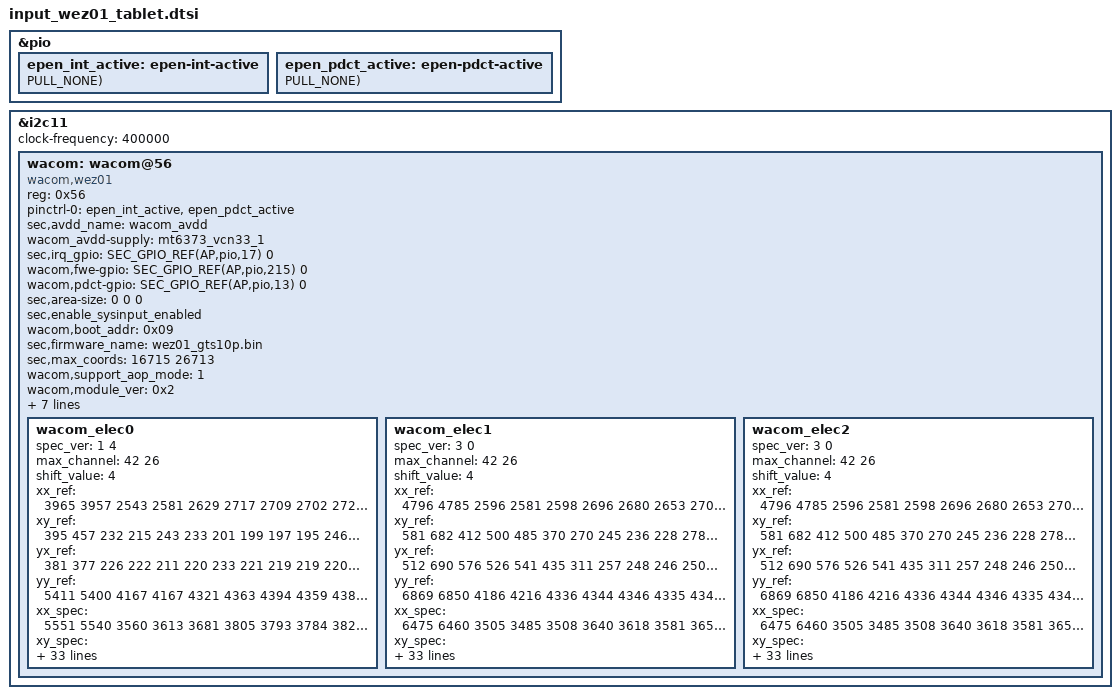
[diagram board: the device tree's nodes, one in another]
&pio {
	epen_int_active: epen-int-active {
		GPIO_CONFIG_PUD(AP,pio,17, FUNC_INPUT_WAKEUP, PULL_NONE);
	};
};

&pio {
	epen_pdct_active: epen-pdct-active {
		GPIO_CONFIG_PUD(AP,pio,13, FUNC_INPUT_WAKEUP, PULL_NONE);
	};
};

&i2c11 {
	status = "ok";
	clock-frequency = <400000>;

	wacom: wacom@56 {
		status = "okay";
		compatible = "wacom,wez01";
		reg = <0x56>;
		pinctrl-names = "default";
		pinctrl-0 = <&epen_int_active &epen_pdct_active>;
		sec,avdd_name = "wacom_avdd";
		wacom_avdd-supply = <&mt6373_vcn33_1>;
		/* gpios */
		sec,irq_gpio = <SEC_GPIO_REF(AP,pio,17) 0>;
		wacom,fwe-gpio = <SEC_GPIO_REF(AP,pio,215) 0>;
		wacom,pdct-gpio = <SEC_GPIO_REF(AP,pio,13) 0>;

		sec,area-size = <0 0 0>; /* recalculate in driver */

		/*support feature*/
		sec,enable_sysinput_enabled;

		/* features */
		wacom,boot_addr = <0x09>;
	};
};

/* /home/dpi/qb5_8814/workspace/P4_1716/android/kernel/kmodule/input/sec_input_2024/wacom/wez01_tablet/dts/input-mtk-wacom.gts10p(wifi).dtsi */
&wacom {
	sec,firmware_name = "wez01_gts10p.bin";
	sec,max_coords = <16715 26713>;

	wacom,support_aop_mode = "1"; /* S-note want to check to use aop */
	wacom,module_ver = <0x2>; /* this value use to distinguish open/short test (0x1 : only open test, 0x2: open/short test) */
	wacom,table_swap = <0x2>; /* bit set: 0 ~ 1(kbd) 1(dex station)*/
	wacom,support_cover_noti;
	wacom,support_cover_detection;
	wacom,support_pogo_cover;
	wacom,support_dual_garage;
	wacom,support_garage_open_test = <0>;
	chip_on_board;

	wacom_elec0 { /* main */
		spec_ver = <1 4>;
		max_channel = <42 26>; /* x y */
		shift_value = <4>;

		xx_ref = /bits/ 64 < 3965 3957 2543 2581 2629 2717 2709 2702 2728 2821 2703 2725 2820 2675 2598 2569 2634 2645 2617 2651 2668 2701 2706 2739 2741 2707 2741 2743 2676 2658 2671 2672 2658 2659 2611 2561 2645 2439 2447 2474 3703 3706 >;
		xy_ref = /bits/ 64 < 395 457 232 215 243 233 201 199 197 195 246 336 277 387 188 131 134 126 141 189 222 210 203 194 180 189 195 141 206 144 222 165 235 136 143 262 145 264 173 328 465 593 >;
		yx_ref = /bits/ 64 < 381 377 226 222 211 220 233 221 219 219 220 225 205 589 327 330 222 242 265 265 233 226 233 243 447 361 >;
		yy_ref = /bits/ 64 < 5411 5400 4167 4167 4321 4363 4394 4359 4386 4404 4408 4406 4401 4406 4404 4351 4406 4425 4391 4405 4426 4391 4249 4144 4700 4703 >;

		xx_spec = /bits/ 64 < 5551 5540 3560 3613 3681 3805 3793 3784 3820 3949 3785 3816 3949 3745 3638 3596 3687 3703 3664 3711 3736 3782 3789 3834 3838 3790 3837 3840 3746 3721 3740 3741 3722 3722 3655 3586 3703 3415 3426 3464 5184 5188 >;
		xy_spec = /bits/ 64 < 553 640 324 302 341 326 282 278 276 273 345 471 388 543 264 184 187 176 197 265 312 294 284 272 253 265 273 197 289 202 311 231 330 190 201 367 203 369 242 459 651 830 >;
		yx_spec = /bits/ 64 < 534 528 317 311 296 308 327 310 307 307 309 316 288 825 458 462 312 340 371 371 326 317 326 340 626 505 >;
		yy_spec = /bits/ 64 < 7575 7560 5835 5834 6049 6108 6152 6102 6141 6165 6171 6168 6162 6168 6165 6091 6168 6195 6147 6167 6196 6147 5948 5802 6581 6584 >;

		rxx_ref = /bits/ 64 < 10000 10000 10000 10000 10000 10000 10000 10000 10000 10000 10000 10000 10000 10000 10000 10000 10000 10000 10000 10000 10000 10000 10000 10000 10000 10000 10000 10000 10000 10000 10000 10000 10000 10000 10000 10000 10000 10000 10000 10000 10000 10000 >;
		rxy_ref = /bits/ 64 < 10000 10000 10000 10000 10000 10000 10000 10000 10000 10000 10000 10000 10000 10000 10000 10000 10000 10000 10000 10000 10000 10000 10000 10000 10000 10000 10000 10000 10000 10000 10000 10000 10000 10000 10000 10000 10000 10000 10000 10000 10000 10000 >;
		ryx_ref = /bits/ 64 < 10000 10000 10000 10000 10000 10000 10000 10000 10000 10000 10000 10000 10000 10000 10000 10000 10000 10000 10000 10000 10000 10000 10000 10000 10000 10000 >;
		ryy_ref = /bits/ 64 < 10000 10000 10000 10000 10000 10000 10000 10000 10000 10000 10000 10000 10000 10000 10000 10000 10000 10000 10000 10000 10000 10000 10000 10000 10000 10000 >;

		drxx_spec = /bits/ 64 < 3500 3500 3500 3500 3500 3500 3500 3500 3500 3500 3500 3500 3500 3500 3500 3500 3500 3500 3500 3500 3500 3500 3500 3500 3500 3500 3500 3500 3500 3500 3500 3500 3500 3500 3500 3500 3500 3500 3500 3500 3500 3500 >;
		drxy_spec = /bits/ 64 < 4000 4000 4000 4000 4000 4000 4000 4000 4000 4000 4000 4000 4000 4000 4000 4000 4000 4000 4000 4000 4000 4000 4000 4000 4000 4000 4000 4000 4000 4000 4000 4000 4000 4000 4000 4000 4000 4000 4000 4000 4000 4000 >;
		dryx_spec = /bits/ 64 < 4000 4000 4000 4000 4000 4000 4000 4000 4000 4000 4000 4000 4000 4000 4000 4000 4000 4000 4000 4000 4000 4000 4000 4000 4000 4000 >;
		dryy_spec = /bits/ 64 < 3500 3500 3500 3500 3500 3500 3500 3500 3500 3500 3500 3500 3500 3500 3500 3500 3500 3500 3500 3500 3500 3500 3500 3500 3500 3500 >;

		drxy_spec_edg = /bits/ 64 < 990000 990000 990000 990000 990000 990000 990000 990000 990000 990000 990000 990000 990000 990000 990000 990000 990000 990000 990000 990000 990000 990000 990000 990000 990000 990000 990000 990000 990000 990000 990000 990000 990000 990000 990000 990000 990000 990000 990000 990000 990000 990000 >;
		dryx_spec_edg = /bits/ 64 < 990000 990000 990000 990000 990000 990000 990000 990000 990000 990000 990000 990000 990000 990000 990000 990000 990000 990000 990000 990000 990000 990000 990000 990000 990000 990000 >;
		xy_ref_edg = /bits/ 64 < 348 384 179 168 111 74 64 68 98 132 153 23 164 38 137 31 66 90 93 152 174 171 163 140 103 68 59 68 97 111 94 80 86 72 44 58 69 77 65 124 362 288 >;
		yx_ref_edg = /bits/ 64 < 310 365 208 188 192 189 191 211 206 206 207 208 175 275 227 221 146 176 211 220 208 211 206 210 362 303 >;

		xx_spec_self = /bits/ 64 < 22000 20000 20000 21000 21000 20000 21000 21000 20000 20000 20000 20000 21000 21000 20000 21000 21000 21000 22000 22000 22000 22000 22000 23000 22000 23000 24000 24000 24000 23000 23000 23000 23000 23000 24000 24000 24000 24000 24000 24000 22000 23000 >;
		yy_spec_self = /bits/ 64 < 25000 25000 25000 25000 25000 25000 25000 25000 25000 25000 25000 25000 25000 25000 25000 25000 25000 25000 25000 25000 25000 25000 25000 25000 25000 25000 >;
	};

	wacom_elec1 { /* assay */
		spec_ver = <3 0>;
		max_channel = <42 26>; /* x y */
		shift_value = <4>;

		xx_ref = /bits/ 64 < 4796 4785 2596 2581 2598 2696 2680 2653 2705 2837 2705 2702 2836 2707 2652 2672 2677 2698 2674 2680 2701 2641 2638 2676 2674 2639 2676 2677 2626 2614 2627 2663 2686 2688 2664 2686 2687 2577 2564 2567 4669 4671 >;
		xy_ref = /bits/ 64 < 581 682 412 500 485 370 270 245 236 228 278 359 350 469 318 264 234 235 241 237 242 238 241 239 239 240 243 246 239 244 238 242 235 219 218 266 246 267 299 428 744 693 >;
		yx_ref = /bits/ 64 < 512 690 576 526 541 435 311 257 248 246 250 287 263 689 358 364 233 237 254 259 302 423 544 581 741 535 >;
		yy_ref = /bits/ 64 < 6869 6850 4186 4216 4336 4344 4346 4335 4348 4357 4356 4352 4350 4368 4389 4370 4386 4397 4371 4383 4395 4362 4310 4242 6176 6181 >;

		xx_spec = /bits/ 64 < 6475 6460 3505 3485 3508 3640 3618 3581 3651 3831 3653 3648 3829 3654 3580 3608 3614 3643 3610 3618 3647 3565 3562 3612 3610 3562 3613 3615 3545 3529 3547 3595 3626 3629 3596 3626 3628 3479 3461 3465 6303 6306 >;
		xy_spec = /bits/ 64 < 784 921 556 676 655 500 365 332 318 308 375 485 473 634 430 357 316 317 325 320 327 322 325 323 323 324 328 332 323 330 322 326 317 296 294 359 332 361 403 578 1004 936 >;
		yx_spec = /bits/ 64 < 692 931 778 710 730 587 420 347 335 333 338 387 356 930 483 492 314 319 343 350 408 571 734 784 1000 722 >;
		yy_spec = /bits/ 64 < 9273 9248 5651 5692 5853 5865 5867 5852 5869 5882 5881 5876 5873 5897 5925 5899 5921 5936 5901 5918 5934 5889 5819 5727 8338 8345 >;

		rxx_ref = /bits/ 64 < 10000 10000 10000 10000 10000 10000 10000 10000 10000 10000 10000 10000 10000 10000 10000 10000 10000 10000 10000 10000 10000 10000 10000 10000 10000 10000 10000 10000 10000 10000 10000 10000 10000 10000 10000 10000 10000 10000 10000 10000 10000 10000 >;
		rxy_ref = /bits/ 64 < 10000 10000 10000 10000 10000 10000 10000 10000 10000 10000 10000 10000 10000 10000 10000 10000 10000 10000 10000 10000 10000 10000 10000 10000 10000 10000 10000 10000 10000 10000 10000 10000 10000 10000 10000 10000 10000 10000 10000 10000 10000 10000 >;
		ryx_ref = /bits/ 64 < 10000 10000 10000 10000 10000 10000 10000 10000 10000 10000 10000 10000 10000 10000 10000 10000 10000 10000 10000 10000 10000 10000 10000 10000 10000 10000 >;
		ryy_ref = /bits/ 64 < 10000 10000 10000 10000 10000 10000 10000 10000 10000 10000 10000 10000 10000 10000 10000 10000 10000 10000 10000 10000 10000 10000 10000 10000 10000 10000 >;

		drxx_spec = /bits/ 64 < 3500 3500 3500 3500 3500 3500 3500 3500 3500 3500 3500 3500 3500 3500 3500 3500 3500 3500 3500 3500 3500 3500 3500 3500 3500 3500 3500 3500 3500 3500 3500 3500 3500 3500 3500 3500 3500 3500 3500 3500 3500 3500 >;
		drxy_spec = /bits/ 64 < 4000 4000 4000 4000 4000 4000 4000 4000 4000 4000 4000 4000 4000 4000 4000 4000 4000 4000 4000 4000 4000 4000 4000 4000 4000 4000 4000 4000 4000 4000 4000 4000 4000 4000 4000 4000 4000 4000 4000 4000 4000 4000 >;
		dryx_spec = /bits/ 64 < 4000 4000 4000 4000 4000 4000 4000 4000 4000 4000 4000 4000 4000 4000 4000 4000 4000 4000 4000 4000 4000 4000 4000 4000 4000 4000 >;
		dryy_spec = /bits/ 64 < 3500 3500 3500 3500 3500 3500 3500 3500 3500 3500 3500 3500 3500 3500 3500 3500 3500 3500 3500 3500 3500 3500 3500 3500 3500 3500 >;

		drxy_spec_edg = /bits/ 64 < 990000 990000 990000 990000 990000 990000 990000 990000 990000 990000 990000 990000 990000 990000 990000 990000 990000 990000 990000 990000 990000 990000 990000 990000 990000 990000 990000 990000 990000 990000 990000 990000 990000 990000 990000 990000 990000 990000 990000 990000 990000 990000 >;
		dryx_spec_edg = /bits/ 64 < 990000 990000 990000 990000 990000 990000 990000 990000 990000 990000 990000 990000 990000 990000 990000 990000 990000 990000 990000 990000 990000 990000 990000 990000 990000 990000 >;
		xy_ref_edg = /bits/ 64 < 446 550 372 269 224 215 212 209 207 206 202 37 186 120 275 127 200 204 205 204 205 203 205 205 207 204 207 208 206 206 204 207 201 176 165 185 214 233 289 400 691 552 >;
		yx_ref_edg = /bits/ 64 < 450 542 432 514 391 289 257 246 238 233 232 231 225 293 247 246 170 201 235 244 268 345 473 566 673 471 >;

		xx_spec_self = /bits/ 64 < 24000 21000 22000 22000 22000 21000 22000 21000 20000 20000 21000 20000 22000 22000 21000 22000 21000 22000 22000 22000 23000 22000 23000 23000 23000 23000 25000 25000 25000 24000 24000 24000 24000 24000 24000 25000 25000 25000 25000 25000 24000 25000 >;
		yy_spec_self = /bits/ 64 < 25000 25000 25000 25000 25000 25000 25000 25000 25000 25000 25000 25000 25000 25000 25000 25000 25000 25000 25000 25000 25000 25000 25000 25000 25000 25000 >;
	};

	wacom_elec2 { /* unit */
		spec_ver = <3 0>;
		max_channel = <42 26>; /* x y */
		shift_value = <4>;

		xx_ref = /bits/ 64 < 4796 4785 2596 2581 2598 2696 2680 2653 2705 2837 2705 2702 2836 2707 2652 2672 2677 2698 2674 2680 2701 2641 2638 2676 2674 2639 2676 2677 2626 2614 2627 2663 2686 2688 2664 2686 2687 2577 2564 2567 4669 4671 >;
		xy_ref = /bits/ 64 < 581 682 412 500 485 370 270 245 236 228 278 359 350 469 318 264 234 235 241 237 242 238 241 239 239 240 243 246 239 244 238 242 235 219 218 266 246 267 299 428 744 693 >;
		yx_ref = /bits/ 64 < 512 690 576 526 541 435 311 257 248 246 250 287 263 689 358 364 233 237 254 259 302 423 544 581 741 535 >;
		yy_ref = /bits/ 64 < 6869 6850 4186 4216 4336 4344 4346 4335 4348 4357 4356 4352 4350 4368 4389 4370 4386 4397 4371 4383 4395 4362 4310 4242 6176 6181 >;

		xx_spec = /bits/ 64 < 6475 6460 3505 3485 3508 3640 3618 3581 3651 3831 3653 3648 3829 3654 3580 3608 3614 3643 3610 3618 3647 3565 3562 3612 3610 3562 3613 3615 3545 3529 3547 3595 3626 3629 3596 3626 3628 3479 3461 3465 6303 6306 >;
		xy_spec = /bits/ 64 < 784 921 556 676 655 500 365 332 318 308 375 485 473 634 430 357 316 317 325 320 327 322 325 323 323 324 328 332 323 330 322 326 317 296 294 359 332 361 403 578 1004 936 >;
		yx_spec = /bits/ 64 < 692 931 778 710 730 587 420 347 335 333 338 387 356 930 483 492 314 319 343 350 408 571 734 784 1000 722 >;
		yy_spec = /bits/ 64 < 9273 9248 5651 5692 5853 5865 5867 5852 5869 5882 5881 5876 5873 5897 5925 5899 5921 5936 5901 5918 5934 5889 5819 5727 8338 8345 >;

		rxx_ref = /bits/ 64 < 10000 10000 10000 10000 10000 10000 10000 10000 10000 10000 10000 10000 10000 10000 10000 10000 10000 10000 10000 10000 10000 10000 10000 10000 10000 10000 10000 10000 10000 10000 10000 10000 10000 10000 10000 10000 10000 10000 10000 10000 10000 10000 >;
		rxy_ref = /bits/ 64 < 10000 10000 10000 10000 10000 10000 10000 10000 10000 10000 10000 10000 10000 10000 10000 10000 10000 10000 10000 10000 10000 10000 10000 10000 10000 10000 10000 10000 10000 10000 10000 10000 10000 10000 10000 10000 10000 10000 10000 10000 10000 10000 >;
		ryx_ref = /bits/ 64 < 10000 10000 10000 10000 10000 10000 10000 10000 10000 10000 10000 10000 10000 10000 10000 10000 10000 10000 10000 10000 10000 10000 10000 10000 10000 10000 >;
		ryy_ref = /bits/ 64 < 10000 10000 10000 10000 10000 10000 10000 10000 10000 10000 10000 10000 10000 10000 10000 10000 10000 10000 10000 10000 10000 10000 10000 10000 10000 10000 >;

		drxx_spec = /bits/ 64 < 3500 3500 3500 3500 3500 3500 3500 3500 3500 3500 3500 3500 3500 3500 3500 3500 3500 3500 3500 3500 3500 3500 3500 3500 3500 3500 3500 3500 3500 3500 3500 3500 3500 3500 3500 3500 3500 3500 3500 3500 3500 3500 >;
		drxy_spec = /bits/ 64 < 4000 4000 4000 4000 4000 4000 4000 4000 4000 4000 4000 4000 4000 4000 4000 4000 4000 4000 4000 4000 4000 4000 4000 4000 4000 4000 4000 4000 4000 4000 4000 4000 4000 4000 4000 4000 4000 4000 4000 4000 4000 4000 >;
		dryx_spec = /bits/ 64 < 4000 4000 4000 4000 4000 4000 4000 4000 4000 4000 4000 4000 4000 4000 4000 4000 4000 4000 4000 4000 4000 4000 4000 4000 4000 4000 >;
		dryy_spec = /bits/ 64 < 3500 3500 3500 3500 3500 3500 3500 3500 3500 3500 3500 3500 3500 3500 3500 3500 3500 3500 3500 3500 3500 3500 3500 3500 3500 3500 >;

		drxy_spec_edg = /bits/ 64 < 990000 990000 990000 990000 990000 990000 990000 990000 990000 990000 990000 990000 990000 990000 990000 990000 990000 990000 990000 990000 990000 990000 990000 990000 990000 990000 990000 990000 990000 990000 990000 990000 990000 990000 990000 990000 990000 990000 990000 990000 990000 990000 >;
		dryx_spec_edg = /bits/ 64 < 990000 990000 990000 990000 990000 990000 990000 990000 990000 990000 990000 990000 990000 990000 990000 990000 990000 990000 990000 990000 990000 990000 990000 990000 990000 990000 >;
		xy_ref_edg = /bits/ 64 < 446 550 372 269 224 215 212 209 207 206 202 37 186 120 275 127 200 204 205 204 205 203 205 205 207 204 207 208 206 206 204 207 201 176 165 185 214 233 289 400 691 552 >;
		yx_ref_edg = /bits/ 64 < 450 542 432 514 391 289 257 246 238 233 232 231 225 293 247 246 170 201 235 244 268 345 473 566 673 471 >;

		xx_spec_self = /bits/ 64 < 24000 21000 22000 22000 22000 21000 22000 21000 20000 20000 21000 20000 22000 22000 21000 22000 21000 22000 22000 22000 23000 22000 23000 23000 23000 23000 25000 25000 25000 24000 24000 24000 24000 24000 24000 25000 25000 25000 25000 25000 24000 25000 >;
		yy_spec_self = /bits/ 64 < 25000 25000 25000 25000 25000 25000 25000 25000 25000 25000 25000 25000 25000 25000 25000 25000 25000 25000 25000 25000 25000 25000 25000 25000 25000 25000 >;
	};
};
